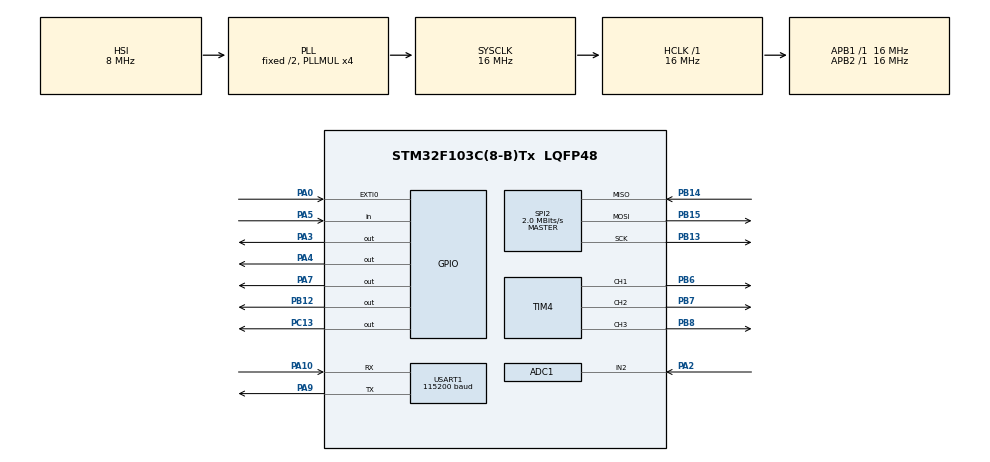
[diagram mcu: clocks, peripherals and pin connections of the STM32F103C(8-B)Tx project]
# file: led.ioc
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ADC1.Channel-11\#ChannelRegularConversion=ADC_CHANNEL_2
ADC1.NbrOfConversionFlag=1
ADC1.Rank-11\#ChannelRegularConversion=1
ADC1.SamplingTime-11\#ChannelRegularConversion=ADC_SAMPLETIME_1CYCLE_5
ADC1.master=1
Mcu.Family=STM32F1
Mcu.Name=STM32F103C(8-B)Tx
Mcu.Package=LQFP48
NVIC.EXTI0_IRQn=true\:1\:0\:true\:false\:true\:true\:true
NVIC.PriorityGroup=NVIC_PRIORITYGROUP_4
NVIC.SPI2_IRQn=true\:3\:0\:true\:false\:true\:true\:true
NVIC.USART1_IRQn=true\:3\:0\:true\:false\:true\:true\:true
PA0-WKUP.Signal=GPXTI0
PA10.Mode=Asynchronous
PA10.Signal=USART1_RX
PA13.Mode=Trace_Asynchronous_SW
PA13.Signal=SYS_JTMS-SWDIO
PA14.Mode=Trace_Asynchronous_SW
PA14.Signal=SYS_JTCK-SWCLK
PA2.Signal=ADCx_IN2
PA3.Signal=GPIO_Output
PA4.Signal=GPIO_Output
PA5.Signal=GPIO_Input
PA7.Signal=GPIO_Output
PA9.Mode=Asynchronous
PA9.Signal=USART1_TX
PB12.Signal=GPIO_Output
PB13.Mode=Full_Duplex_Master
PB13.Signal=SPI2_SCK
PB14.Mode=Full_Duplex_Master
PB14.Signal=SPI2_MISO
PB15.Mode=Full_Duplex_Master
PB15.Signal=SPI2_MOSI
PB3.Mode=Trace_Asynchronous_SW
PB3.Signal=SYS_JTDO-TRACESWO
PB6.Signal=S_TIM4_CH1
PB7.Signal=S_TIM4_CH2
PB8.Signal=S_TIM4_CH3
PC13-TAMPER-RTC.Signal=GPIO_Output
PD0-OSC_IN.Mode=HSE-External-Oscillator
PD0-OSC_IN.Signal=RCC_OSC_IN
PD1-OSC_OUT.Mode=HSE-External-Oscillator
PD1-OSC_OUT.Signal=RCC_OSC_OUT
ProjectManager.HeapSize=0x200
ProjectManager.StackSize=0x400
ProjectManager.TargetToolchain=MDK-ARM V5
RCC.AHBFreq_Value=16000000
RCC.APB1Freq_Value=16000000
RCC.APB1TimFreq_Value=16000000
RCC.APB2Freq_Value=16000000
RCC.APB2TimFreq_Value=16000000
RCC.HCLKFreq_Value=16000000
RCC.HSE_VALUE=12000000
RCC.PLLMUL=RCC_PLL_MUL4
RCC.SYSCLKFreq_VALUE=16000000
RCC.SYSCLKSource=RCC_SYSCLKSOURCE_PLLCLK
RCC.USBFreq_Value=16000000
SH.ADCx_IN2.0=ADC1_IN2,IN2
SH.S_TIM4_CH1.0=TIM4_CH1,PWM Generation1 CH1
SH.S_TIM4_CH2.0=TIM4_CH2,PWM Generation2 CH2
SH.S_TIM4_CH3.0=TIM4_CH3,PWM Generation3 CH3
SPI2.BaudRatePrescaler=SPI_BAUDRATEPRESCALER_8
SPI2.CalculateBaudRate=2.0 MBits/s
SPI2.Direction=SPI_DIRECTION_2LINES
SPI2.Mode=SPI_MODE_MASTER
SPI2.VirtualType=VM_MASTER
TIM4.Channel-PWM\ Generation1\ CH1=TIM_CHANNEL_1
TIM4.Channel-PWM\ Generation2\ CH2=TIM_CHANNEL_2
TIM4.Channel-PWM\ Generation3\ CH3=TIM_CHANNEL_3
USART1.BaudRate=115200
USART1.VirtualMode=VM_ASYNC
board=custom

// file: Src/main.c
/* USER CODE BEGIN Header */
/**
  ******************************************************************************
  * @file           : main.c
  * @brief          : Main program body
  ******************************************************************************
  * @attention
  *
  * <h2><center>&copy; Copyright (c) 2019 STMicroelectronics.
  * All rights reserved.</center></h2>
  *
  * This software component is licensed by ST under BSD 3-Clause license,
  * the "License"; You may not use this file except in compliance with the
  * License. You may obtain a copy of the License at:
  *                        opensource.org/licenses/BSD-3-Clause
  *
  ******************************************************************************
  */
/* USER CODE END Header */

#include "main.h"

ADC_HandleTypeDef hadc1;

SPI_HandleTypeDef hspi2;

TIM_HandleTypeDef htim4;

UART_HandleTypeDef huart1;

void SystemClock_Config(void);
static void MX_GPIO_Init(void);
static void MX_USART1_UART_Init(void);
static void MX_ADC1_Init(void);
static void MX_SPI2_Init(void);
static void MX_TIM4_Init(void);

int main(void)
{

  /* MCU Configuration--------------------------------------------------------*/

  /* Reset of all peripherals, Initializes the Flash interface and the Systick. */
  HAL_Init();

  /* Configure the system clock */
  SystemClock_Config();

  /* Initialize all configured peripherals */
  MX_GPIO_Init();
  MX_USART1_UART_Init();
  MX_ADC1_Init();
  MX_SPI2_Init();
  MX_TIM4_Init();
  /* USER CODE BEGIN 2 */
        HAL_TIM_PWM_Start(&htim4, TIM_CHANNEL_1);
        HAL_TIM_PWM_Start(&htim4, TIM_CHANNEL_2);
        HAL_TIM_PWM_Start(&htim4, TIM_CHANNEL_3);
  /* USER CODE END 2 */

  /* Infinite loop */
  /* USER CODE BEGIN WHILE */
  while (1)
  {
		for(uint16_t l=0;l<=255;l++){ TIM4->CCR1=255; TIM4->CCR2= 0; TIM4->CCR3=l;	HAL_Delay(50);}//255 0 .255
		for(uint16_t l=255;l!=0;l--){ TIM4->CCR1=l; TIM4->CCR2= 0; TIM4->CCR3=255;	HAL_Delay(5);}// .0 0 255
		for(uint16_t l=0;l<=255;l++){ TIM4->CCR1=0; TIM4->CCR2= l; TIM4->CCR3=255;	HAL_Delay(5);}// 0 .255 255
		for(uint16_t l=255;l!=0;l--){ TIM4->CCR1=0; TIM4->CCR2= 255; TIM4->CCR3=l;	HAL_Delay(5);}// 0 255 .0
		for(uint16_t l=0;l<=255;l++){ TIM4->CCR1=l; TIM4->CCR2= 255; TIM4->CCR3=0;	HAL_Delay(5);}// .255 255 0
		for(uint16_t l=255;l!=0;l--){ TIM4->CCR1=255; TIM4->CCR2= l; TIM4->CCR3=0;	HAL_Delay(5);}//255 .0 0

    /* USER CODE END WHILE */
		HAL_GPIO_WritePin(GPIOA,GPIO_PIN_3,GPIO_PIN_SET);
		HAL_Delay(1000);
		HAL_GPIO_WritePin(GPIOA,GPIO_PIN_4,GPIO_PIN_SET);
		HAL_Delay(1000);
		HAL_GPIO_WritePin(GPIOA,GPIO_PIN_3,GPIO_PIN_RESET);
		HAL_Delay(1000);
		HAL_GPIO_WritePin(GPIOA,GPIO_PIN_4,GPIO_PIN_RESET);
		HAL_Delay(1000);
  }
}

void SystemClock_Config(void)
{
  RCC_OscInitTypeDef RCC_OscInitStruct = {0};
  RCC_ClkInitTypeDef RCC_ClkInitStruct = {0};
  RCC_PeriphCLKInitTypeDef PeriphClkInit = {0};

  /** Initializes the CPU, AHB and APB busses clocks
  */
  RCC_OscInitStruct.OscillatorType = RCC_OSCILLATORTYPE_HSI;
  RCC_OscInitStruct.HSIState = RCC_HSI_ON;
  RCC_OscInitStruct.HSICalibrationValue = RCC_HSICALIBRATION_DEFAULT;
  RCC_OscInitStruct.PLL.PLLState = RCC_PLL_ON;
  RCC_OscInitStruct.PLL.PLLSource = RCC_PLLSOURCE_HSI_DIV2;
  RCC_OscInitStruct.PLL.PLLMUL = RCC_PLL_MUL4;
  if (HAL_RCC_OscConfig(&RCC_OscInitStruct) != HAL_OK)
  {
    Error_Handler();
  }
  /** Initializes the CPU, AHB and APB busses clocks
  */
  RCC_ClkInitStruct.ClockType = RCC_CLOCKTYPE_HCLK|RCC_CLOCKTYPE_SYSCLK
                              |RCC_CLOCKTYPE_PCLK1|RCC_CLOCKTYPE_PCLK2;
  RCC_ClkInitStruct.SYSCLKSource = RCC_SYSCLKSOURCE_PLLCLK;
  RCC_ClkInitStruct.AHBCLKDivider = RCC_SYSCLK_DIV1;
  RCC_ClkInitStruct.APB1CLKDivider = RCC_HCLK_DIV1;
  RCC_ClkInitStruct.APB2CLKDivider = RCC_HCLK_DIV1;

  if (HAL_RCC_ClockConfig(&RCC_ClkInitStruct, FLASH_LATENCY_0) != HAL_OK)
  {
    Error_Handler();
  }
  PeriphClkInit.PeriphClockSelection = RCC_PERIPHCLK_ADC;
  PeriphClkInit.AdcClockSelection = RCC_ADCPCLK2_DIV2;
  if (HAL_RCCEx_PeriphCLKConfig(&PeriphClkInit) != HAL_OK)
  {
    Error_Handler();
  }
}

static void MX_ADC1_Init(void)
{

  ADC_ChannelConfTypeDef sConfig = {0};

  /** Common config
  */
  hadc1.Instance = ADC1;
  hadc1.Init.ScanConvMode = ADC_SCAN_DISABLE;
  hadc1.Init.ContinuousConvMode = DISABLE;
  hadc1.Init.DiscontinuousConvMode = DISABLE;
  hadc1.Init.ExternalTrigConv = ADC_SOFTWARE_START;
  hadc1.Init.DataAlign = ADC_DATAALIGN_RIGHT;
  hadc1.Init.NbrOfConversion = 1;
  if (HAL_ADC_Init(&hadc1) != HAL_OK)
  {
    Error_Handler();
  }
  /** Configure Regular Channel
  */
  sConfig.Channel = ADC_CHANNEL_2;
  sConfig.Rank = ADC_REGULAR_RANK_1;
  sConfig.SamplingTime = ADC_SAMPLETIME_1CYCLE_5;
  if (HAL_ADC_ConfigChannel(&hadc1, &sConfig) != HAL_OK)
  {
    Error_Handler();
  }

}

static void MX_SPI2_Init(void)
{

  /* SPI2 parameter configuration*/
  hspi2.Instance = SPI2;
  hspi2.Init.Mode = SPI_MODE_MASTER;
  hspi2.Init.Direction = SPI_DIRECTION_2LINES;
  hspi2.Init.DataSize = SPI_DATASIZE_8BIT;
  hspi2.Init.CLKPolarity = SPI_POLARITY_LOW;
  hspi2.Init.CLKPhase = SPI_PHASE_1EDGE;
  hspi2.Init.NSS = SPI_NSS_SOFT;
  hspi2.Init.BaudRatePrescaler = SPI_BAUDRATEPRESCALER_8;
  hspi2.Init.FirstBit = SPI_FIRSTBIT_MSB;
  hspi2.Init.TIMode = SPI_TIMODE_DISABLE;
  hspi2.Init.CRCCalculation = SPI_CRCCALCULATION_DISABLE;
  hspi2.Init.CRCPolynomial = 10;
  if (HAL_SPI_Init(&hspi2) != HAL_OK)
  {
    Error_Handler();
  }

}

static void MX_TIM4_Init(void)
{

  TIM_MasterConfigTypeDef sMasterConfig = {0};
  TIM_OC_InitTypeDef sConfigOC = {0};

  htim4.Instance = TIM4;
  htim4.Init.Prescaler = 0;
  htim4.Init.CounterMode = TIM_COUNTERMODE_UP;
  htim4.Init.Period = 255 ;
  htim4.Init.ClockDivision = TIM_CLOCKDIVISION_DIV1;
  htim4.Init.AutoReloadPreload = TIM_AUTORELOAD_PRELOAD_DISABLE;
  if (HAL_TIM_PWM_Init(&htim4) != HAL_OK)
  {
    Error_Handler();
  }
  sMasterConfig.MasterOutputTrigger = TIM_TRGO_RESET;
  sMasterConfig.MasterSlaveMode = TIM_MASTERSLAVEMODE_DISABLE;
  if (HAL_TIMEx_MasterConfigSynchronization(&htim4, &sMasterConfig) != HAL_OK)
  {
    Error_Handler();
  }
  sConfigOC.OCMode = TIM_OCMODE_PWM1;
  sConfigOC.Pulse = 0;
  sConfigOC.OCPolarity = TIM_OCPOLARITY_HIGH;
  sConfigOC.OCFastMode = TIM_OCFAST_DISABLE;
  if (HAL_TIM_PWM_ConfigChannel(&htim4, &sConfigOC, TIM_CHANNEL_1) != HAL_OK)
  {
    Error_Handler();
  }
  if (HAL_TIM_PWM_ConfigChannel(&htim4, &sConfigOC, TIM_CHANNEL_2) != HAL_OK)
  {
    Error_Handler();
  }
  if (HAL_TIM_PWM_ConfigChannel(&htim4, &sConfigOC, TIM_CHANNEL_3) != HAL_OK)
  {
    Error_Handler();
  }
  HAL_TIM_MspPostInit(&htim4);

}

static void MX_USART1_UART_Init(void)
{

  huart1.Instance = USART1;
  huart1.Init.BaudRate = 115200;
  huart1.Init.WordLength = UART_WORDLENGTH_8B;
  huart1.Init.StopBits = UART_STOPBITS_1;
  huart1.Init.Parity = UART_PARITY_NONE;
  huart1.Init.Mode = UART_MODE_TX_RX;
  huart1.Init.HwFlowCtl = UART_HWCONTROL_NONE;
  huart1.Init.OverSampling = UART_OVERSAMPLING_16;
  if (HAL_UART_Init(&huart1) != HAL_OK)
  {
    Error_Handler();
  }

}

static void MX_GPIO_Init(void)
{
  GPIO_InitTypeDef GPIO_InitStruct = {0};

  /* GPIO Ports Clock Enable */
  __HAL_RCC_GPIOC_CLK_ENABLE();
  __HAL_RCC_GPIOD_CLK_ENABLE();
  __HAL_RCC_GPIOA_CLK_ENABLE();
  __HAL_RCC_GPIOB_CLK_ENABLE();

  /*Configure GPIO pin Output Level */
  HAL_GPIO_WritePin(GPIOC, GPIO_PIN_13, GPIO_PIN_RESET);

  /*Configure GPIO pin Output Level */
  HAL_GPIO_WritePin(GPIOA, GPIO_PIN_3|GPIO_PIN_4|GPIO_PIN_7, GPIO_PIN_RESET);

  /*Configure GPIO pin Output Level */
  HAL_GPIO_WritePin(GPIOB, GPIO_PIN_12, GPIO_PIN_RESET);

  /*Configure GPIO pin : PC13 */
  GPIO_InitStruct.Pin = GPIO_PIN_13;
  GPIO_InitStruct.Mode = GPIO_MODE_OUTPUT_PP;
  GPIO_InitStruct.Pull = GPIO_NOPULL;
  GPIO_InitStruct.Speed = GPIO_SPEED_FREQ_LOW;
  HAL_GPIO_Init(GPIOC, &GPIO_InitStruct);

  /*Configure GPIO pin : PA0 */
  GPIO_InitStruct.Pin = GPIO_PIN_0;
  GPIO_InitStruct.Mode = GPIO_MODE_IT_RISING;
  GPIO_InitStruct.Pull = GPIO_NOPULL;
  HAL_GPIO_Init(GPIOA, &GPIO_InitStruct);

  /*Configure GPIO pins : PA3 PA4 PA7 */
  GPIO_InitStruct.Pin = GPIO_PIN_3|GPIO_PIN_4|GPIO_PIN_7;
  GPIO_InitStruct.Mode = GPIO_MODE_OUTPUT_PP;
  GPIO_InitStruct.Pull = GPIO_NOPULL;
  GPIO_InitStruct.Speed = GPIO_SPEED_FREQ_LOW;
  HAL_GPIO_Init(GPIOA, &GPIO_InitStruct);

  /*Configure GPIO pin : PA5 */
  GPIO_InitStruct.Pin = GPIO_PIN_5;
  GPIO_InitStruct.Mode = GPIO_MODE_INPUT;
  GPIO_InitStruct.Pull = GPIO_NOPULL;
  HAL_GPIO_Init(GPIOA, &GPIO_InitStruct);

  /*Configure GPIO pin : PB12 */
  GPIO_InitStruct.Pin = GPIO_PIN_12;
  GPIO_InitStruct.Mode = GPIO_MODE_OUTPUT_PP;
  GPIO_InitStruct.Pull = GPIO_NOPULL;
  GPIO_InitStruct.Speed = GPIO_SPEED_FREQ_LOW;
  HAL_GPIO_Init(GPIOB, &GPIO_InitStruct);

  /* EXTI interrupt init*/
  HAL_NVIC_SetPriority(EXTI0_IRQn, 1, 0);
  HAL_NVIC_EnableIRQ(EXTI0_IRQn);

}

void Error_Handler(void)
{
}

/************************ (C) COPYRIGHT STMicroelectronics *****END OF FILE****/
